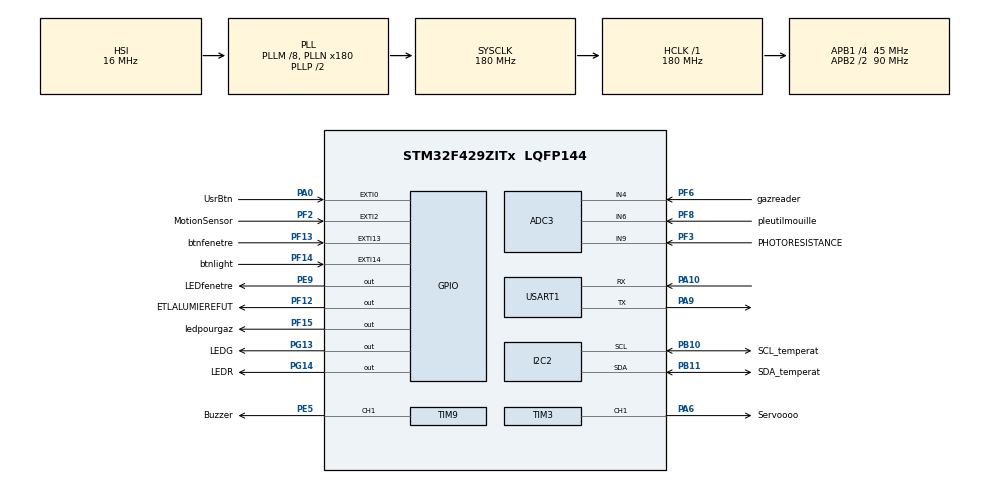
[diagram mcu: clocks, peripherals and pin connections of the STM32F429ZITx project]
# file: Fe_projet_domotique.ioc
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ADC3.Channel-0\#ChannelRegularConversion=ADC_CHANNEL_9
ADC3.NbrOfConversionFlag=1
ADC3.Rank-0\#ChannelRegularConversion=1
ADC3.SamplingTime-0\#ChannelRegularConversion=ADC_SAMPLETIME_3CYCLES
Mcu.Family=STM32F4
Mcu.Name=STM32F429ZITx
Mcu.Package=LQFP144
NVIC.EXTI0_IRQn=true\:0\:0\:false\:false\:true\:true\:true\:true
NVIC.EXTI15_10_IRQn=true\:0\:0\:false\:false\:true\:true\:true\:true
NVIC.EXTI2_IRQn=true\:0\:0\:false\:false\:true\:true\:true\:true
NVIC.PriorityGroup=NVIC_PRIORITYGROUP_4
NVIC.TIM1_BRK_TIM9_IRQn=true\:0\:0\:false\:false\:true\:true\:true\:true
NVIC.TIM2_IRQn=true\:0\:0\:false\:false\:true\:true\:true\:true
PA0/WKUP.GPIO_Label=UsrBtn
PA0/WKUP.GPIO_ModeDefaultEXTI=GPIO_MODE_IT_RISING
PA0/WKUP.Signal=GPXTI0
PA10.Mode=Asynchronous
PA10.Signal=USART1_RX
PA6.GPIO_Label=Servoooo
PA6.Signal=S_TIM3_CH1
PA9.Mode=Asynchronous
PA9.Signal=USART1_TX
PB10.GPIO_Label=SCL_temperat
PB10.Mode=I2C
PB10.Signal=I2C2_SCL
PB11.GPIO_Label=SDA_temperat
PB11.Mode=I2C
PB11.Signal=I2C2_SDA
PE5.GPIO_Label=Buzzer
PE5.Signal=S_TIM9_CH1
PE9.GPIO_Label=LEDfenetre
PE9.Signal=GPIO_Output
PF12.GPIO_Label=ETLALUMIEREFUT
PF12.Signal=GPIO_Output
PF13.GPIO_Label=btnfenetre
PF13.Signal=GPXTI13
PF14.GPIO_Label=btnlight
PF14.Signal=GPXTI14
PF15.GPIO_Label=ledpourgaz
PF15.Signal=GPIO_Output
PF2.GPIO_Label=MotionSensor
PF2.GPIO_ModeDefaultEXTI=GPIO_MODE_IT_RISING
PF2.Signal=GPXTI2
PF3.GPIO_Label=PHOTORESISTANCE
PF3.Mode=IN9
PF3.Signal=ADC3_IN9
PF6.GPIO_Label=gazreader
PF6.Mode=IN4
PF6.Signal=ADC3_IN4
PF8.GPIO_Label=pleutilmouille
PF8.Mode=IN6
PF8.Signal=ADC3_IN6
PG13.GPIO_Label=LEDG
PG13.Signal=GPIO_Output
PG14.GPIO_Label=LEDR
PG14.Signal=GPIO_Output
ProjectManager.HeapSize=0x200
ProjectManager.StackSize=0x400
ProjectManager.TargetToolchain=STM32CubeIDE
RCC.48MHZClocksFreq_Value=90000000
RCC.AHBFreq_Value=180000000
RCC.APB1CLKDivider=RCC_HCLK_DIV4
RCC.APB1Freq_Value=45000000
RCC.APB1TimFreq_Value=90000000
RCC.APB2CLKDivider=RCC_HCLK_DIV2
RCC.APB2Freq_Value=90000000
RCC.APB2TimFreq_Value=180000000
RCC.CortexFreq_Value=180000000
RCC.HCLKFreq_Value=180000000
RCC.HSE_VALUE=25000000
RCC.HSI_VALUE=16000000
RCC.LSE_VALUE=32768
RCC.PLLM=8
RCC.PLLN=180
RCC.SYSCLKFreq_VALUE=180000000
RCC.SYSCLKSource=RCC_SYSCLKSOURCE_PLLCLK
RCC.VCOOutputFreq_Value=360000000
SH.S_TIM3_CH1.0=TIM3_CH1,PWM Generation1 CH1
SH.S_TIM9_CH1.0=TIM9_CH1,PWM Generation1 CH1
TIM2.AutoReloadPreload=TIM_AUTORELOAD_PRELOAD_ENABLE
TIM2.ClockDivision=TIM_CLOCKDIVISION_DIV1
TIM2.Period=719
TIM2.Prescaler=62499
TIM3.Channel-PWM\ Generation1\ CH1=TIM_CHANNEL_1
TIM3.Period=19999
TIM3.Prescaler=89
TIM3.Pulse-PWM\ Generation1\ CH1=1000
TIM9.AutoReloadPreload=TIM_AUTORELOAD_PRELOAD_DISABLE
TIM9.Channel-PWM\ Generation1\ CH1=TIM_CHANNEL_1
TIM9.Period=562
TIM9.Prescaler=624
TIM9.Pulse-PWM\ Generation1\ CH1=281
USART1.VirtualMode=VM_ASYNC
VP_TIM2_VS_ClockSourceINT.Mode=Internal
VP_TIM3_VS_ClockSourceINT.Mode=Internal
VP_TIM9_VS_ClockSourceINT.Mode=Internal
board=custom

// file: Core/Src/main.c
/* USER CODE BEGIN Header */
//main.c

/* USER CODE END Header */
#include "main.h"
#include "adc.h"
#include "i2c.h"
#include "tim.h"
#include "usart.h"
#include "gpio.h"

/* USER CODE BEGIN Includes */
#include "Code.h"
/* USER CODE END Includes */

void SystemClock_Config(void);

int main(void)
{

  /* MCU Configuration--------------------------------------------------------*/

  /* Reset of all peripherals, Initializes the Flash interface and the Systick. */
  HAL_Init();

  /* Configure the system clock */
  SystemClock_Config();

  /* Initialize all configured peripherals */
  MX_GPIO_Init();
  MX_TIM9_Init();
  MX_TIM2_Init();
  MX_USART1_UART_Init();
  MX_ADC3_Init();
  MX_TIM3_Init();
  MX_I2C2_Init();
  /* USER CODE BEGIN 2 */
  Init();
  HAL_TIM_PWM_Start(&htim3,TIM_CHANNEL_2);
  /* USER CODE END 2 */

  /* Infinite loop */
  /* USER CODE BEGIN WHILE */
	while(1){
		Loop();
    /* USER CODE END WHILE */

	}
}

void SystemClock_Config(void)
{
  RCC_OscInitTypeDef RCC_OscInitStruct = {0};
  RCC_ClkInitTypeDef RCC_ClkInitStruct = {0};

  /** Configure the main internal regulator output voltage
  */
  __HAL_RCC_PWR_CLK_ENABLE();
  __HAL_PWR_VOLTAGESCALING_CONFIG(PWR_REGULATOR_VOLTAGE_SCALE1);

  /** Initializes the RCC Oscillators according to the specified parameters
  * in the RCC_OscInitTypeDef structure.
  */
  RCC_OscInitStruct.OscillatorType = RCC_OSCILLATORTYPE_HSI;
  RCC_OscInitStruct.HSIState = RCC_HSI_ON;
  RCC_OscInitStruct.HSICalibrationValue = RCC_HSICALIBRATION_DEFAULT;
  RCC_OscInitStruct.PLL.PLLState = RCC_PLL_ON;
  RCC_OscInitStruct.PLL.PLLSource = RCC_PLLSOURCE_HSI;
  RCC_OscInitStruct.PLL.PLLM = 8;
  RCC_OscInitStruct.PLL.PLLN = 180;
  RCC_OscInitStruct.PLL.PLLP = RCC_PLLP_DIV2;
  RCC_OscInitStruct.PLL.PLLQ = 4;
  if (HAL_RCC_OscConfig(&RCC_OscInitStruct) != HAL_OK)
  {
    Error_Handler();
  }

  /** Activate the Over-Drive mode
  */
  if (HAL_PWREx_EnableOverDrive() != HAL_OK)
  {
    Error_Handler();
  }

  /** Initializes the CPU, AHB and APB buses clocks
  */
  RCC_ClkInitStruct.ClockType = RCC_CLOCKTYPE_HCLK|RCC_CLOCKTYPE_SYSCLK
                              |RCC_CLOCKTYPE_PCLK1|RCC_CLOCKTYPE_PCLK2;
  RCC_ClkInitStruct.SYSCLKSource = RCC_SYSCLKSOURCE_PLLCLK;
  RCC_ClkInitStruct.AHBCLKDivider = RCC_SYSCLK_DIV1;
  RCC_ClkInitStruct.APB1CLKDivider = RCC_HCLK_DIV4;
  RCC_ClkInitStruct.APB2CLKDivider = RCC_HCLK_DIV2;

  if (HAL_RCC_ClockConfig(&RCC_ClkInitStruct, FLASH_LATENCY_5) != HAL_OK)
  {
    Error_Handler();
  }
}

void Error_Handler(void)
{
  /* USER CODE BEGIN Error_Handler_Debug */
	/* User can add his own implementation to report the HAL error return state */
	__disable_irq();
	while(1);//Crash
  /* USER CODE END Error_Handler_Debug */
}
